# CM_CORE__CKGEN register map
Vendor: Texas Instruments
Peripheral module from a debugger description file (folder TDA2Ex).
Registers are 32-bit, access per field, reset 0x0 unless marked. A register's access mark holds for its fields unless they carry their own. Offsets are as the file gives them; lines under a group give offsets from that group; [hi:lo] are bit positions; {n}, {i} and the like mark numbered series; 'fields as' and 'values as' point back to an identical list; <NAME> marks a mode.

## CM_CORE__CKGEN
0x04 CM_CLKSEL_USB_60MHZ reset 0x1 — Selects the configuration of the divider generating 60MHz clock for USB from the DPLL_USB o/p.
  [0] CLKSEL rw — Select the configuration of the divider
    0=SEL_DIV_1 (Set the divider in bypass mode to support bypass clock from DPLL_USB to pass through without division.); 1=SEL_DIV_8 (Set the divider to divide the DPLL o/p (480MHz typical) by 8 to generate 60MHz clock.)
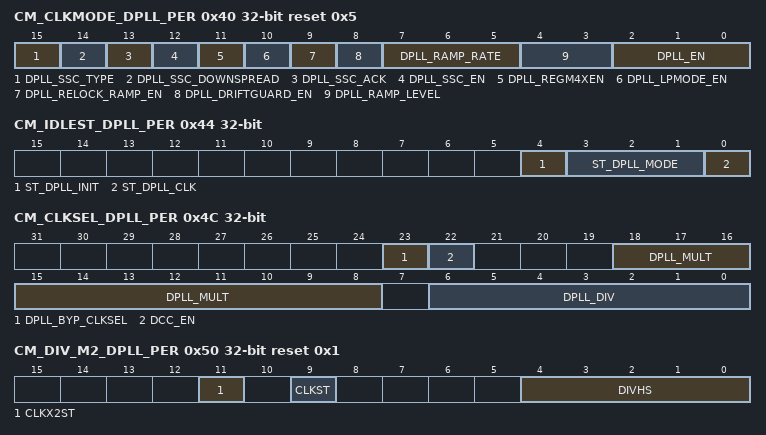
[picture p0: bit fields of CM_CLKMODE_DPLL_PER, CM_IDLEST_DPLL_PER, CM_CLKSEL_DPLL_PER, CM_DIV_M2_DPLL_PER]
0x40 CM_CLKMODE_DPLL_PER reset 0x5 — This register allows controlling the DPLL modes.
  [15] DPLL_SSC_TYPE rw — Select between Triangular and SquareWave Spread Spectrum Clocking
    0=TRIANGULAR (Triangular Spread Spectrum Clocking is selected); 1=SQUARE (Square Wave Spread Spectrum Clocking is selected (only available under proper licensing agreement))
  [14] DPLL_SSC_DOWNSPREAD rw — Control if only low frequency spread is required
    0=FULL_SPREAD (When SSC is enabled, clock frequency is spread on both sides of the programmed frequency); 1=LOW_SPREAD (When SSC is enabled, clock frequency is spread only on the lower side of the programmed frequency)
  [13] DPLL_SSC_ACK ro — Acknowledgement from the DPLL regarding start and stop of Spread Spectrum Clocking feature
    0=DISABLED (SSC has been turned off on PLL o/ps); 1=ENABLED (SSC has been turned on on PLL o/ps)
  [12] DPLL_SSC_EN rw — Enable or disable Spread Spectrum Clocking
    0=DISABLED (SSC disabled); 1=ENABLED (SSC enabled)
  [11] DPLL_REGM4XEN ro — Enable the REGM4XEN mode of the DPLL. Please check the DPLL documentation to check when this mode can be enabled.
    0=DISABLED (REGM4XEN mode of the DPLL is disabled)
  [10] DPLL_LPMODE_EN rw — Set the DPLL in Low Power mode. Check the DPLL documentation to see when this can be enabled.
    0=DISABLED (Low power mode of the DPLL is disabled); 1=ENABLED (Low power mode of the DPLL is enabled)
  [9] DPLL_RELOCK_RAMP_EN rw — If enabled, the clock ramping feature is used applied during the lock process, as well as the relock process. If disabled, the clock ramping feature is used only during the first lock.
  [8] DPLL_DRIFTGUARD_EN rw — This bit allows to enable or disable the automatic recalibration feature of the DPLL. The DPLL will automatically start a recalibration process upon assertion of the DPLL's RECAL flag if this bit is set.
    0=DIASBLED (DRIFTGUARD feature is disabled); 1=ENABLED (DRIFTGUARD feature is enabled)
  [7:5] DPLL_RAMP_RATE rw — Selects the time in terms of DPLL REFCLKs spent at each stage of the clock ramping process
    0=REFCLKX2 (2 REFCLKs); 1=REFCLKX4 (4 REFCLKs); 2=REFCLKX8 (8 REFCLKs); 3=REFCLKX16 (16 REFCLKs); 4=REFCLKX32 (32 REFCLKs); 5=REFCLKX64 (64 REFCLKs); 6=REFCLKX128 (128 REFCLKs); 7=REFCLKX512 (512 REFCLKs)
  [4:3] DPLL_RAMP_LEVEL rw — The DPLL provides an output clock frequency ramping feature when switching from bypass clock to normal clock during lock and re-lock. The frequency ramping will happen in a maximum of 4 steps in frequency before the DPLL's frequency lock indicator is asserted. This register is used to enable/disable the DPLL ramping feature. If enabled, it is also used to select the algorithm used for clock ramping
    0=RAMP_DISABLE (CLKOUT = No ramping CLKOUTX2 = No ramping); 1=RAMP_ALGO1 (CLKOUT = Bypass clk - Fout/8 - Fout/4 - Fout/2 - Fout CLKOUTX2 = Bypass clk - Foutx2/8 - Foutx2/4 - Foutx2/2 - Foutx2); 2=RAMP_ALGO2 (CLKOUT = Bypass clk - Fout/4 - Fout/2 - Fout/1.5 - Fout CLKOUTX2 = Bypass clk - Foutx2/4 - Foutx2/2 - Foutx2/1.5 - Foutx2)
  [2:0] DPLL_EN rw — DPLL control.
    5=DPLL_LP_BYP_MODE (Put the DPLL in Idle Bypass Low Power mode.); 6=DPLL_FR_BYP_MODE (Put the DPLL in Idle Bypass Fast Relock mode.); 7=DPLL_LOCK_MODE (Enables the DPLL in Lock mode)
0x44 CM_IDLEST_DPLL_PER ro — This register allows monitoring DPLL activity. This register is read only and automatically updated. [warm reset insensitive]
  [4] ST_DPLL_INIT — DPLL init status (for debug purpose).
    0=DPLL_NOTINIT (DPLL is not init); 1=DPLL_INIT (DPLL has been init)
  [3:1] ST_DPLL_MODE — DPLL mode status (for debug purpose).
    0=TRANSIENT (Transient state. From reset to any LP idle state or from any power state to any power state (Power states are Low Power Stop mode, Fast Relock Stop mode, Idle Bypass Low Power mode and Idle Bypass Fast Relock mode).); 1=LP_STOP (The DPLL is in Low Power Stop mode.); 2=FR_STOP (The DPLL is in Fast Relock Stop mode.); 5=LP_BYP (The DPLL is in Idle Bypass Low Power mode.); 6=FR_BYP (The DPLL is in Idle Bypass Fast Relock mode.)
  [0] ST_DPLL_CLK — DPLL lock status
    0=DPLL_UNLOCKED (DPLL is either in bypass mode or in stop mode.); 1=DPLL_LOCKED (DPLL is LOCKED)
0x48 CM_AUTOIDLE_DPLL_PER — This register provides automatic control over the DPLL activity.
  [2:0] AUTO_DPLL_MODE rw — DPLL automatic control;
    0=AUTO_CTL_DISABLE (DPLL auto control disabled); 1=AUTO_LP_STOP (The DPLL is automatically put in Low Power Stop mode when its DPLL generated clocks are not required anymore. It is also restarted automatically.); 2=AUTO_FR_STOP (The DPLL is automatically put in Fast Relock Stop mode when its DPLL generated clocks are not required anymore. It is also restarted automatically.); 5=AUTO_LP_BYP (The DPLL is automatically put in Idle Bypass Low Power mode when its DPLL generated clocks are not required anymore. It is also restarted automatically.); 6=AUTO_FR_BYP (The DPLL is automatically put in Idle Bypass Fast Relock mode when its DPLL generated clocks are not required anymore. It is also restarted automatically.)
0x4C CM_CLKSEL_DPLL_PER — This register provides controls over the DPLL.
  [23] DPLL_BYP_CLKSEL rw — Allows control of the BYPASS clock of the PLL and the associated HSDIVIDER. Same as ULOWCLKEN on DPLL. In DPLL Locked mode, 0 - No impact 1 - No impact In DPLL Bypass mode, 0 - CLKINP is selected as the BYPASS clock for CLKOUT/CLKOUTX2 1 - CLKINPULOW is selected as the BYPASS clock for CLKOUT/CLKOUTX2
  [22] DCC_EN ro — Duty-cycle corrector for high frequency clock
    0=DISABLED (Duty-cycle corrector is disabled)
  [18:8] DPLL_MULT rw — DPLL multiplier factor (2 to 2047). (equal to input M of DPLL; M=2 to 2047 = DPLL multiplies by M). [warm reset insensitive]
  [6:0] DPLL_DIV rw — DPLL divider factor (0 to 127) (equal to input N of DPLL; actual division factor is N+1). [warm reset insensitive]
0x50 CM_DIV_M2_DPLL_PER reset 0x1 — This register provides controls over the M2 divider of the DPLL.
  [11] CLKX2ST ro — DPLL CLKOUTX2 status
    0=CLK_GATED (The clock output is gated); 1=CLK_ENABLED (The clock output is enabled)
  [9] CLKST ro — DPLL CLKOUT status
    values as CLKX2ST
  [4:0] DIVHS rw — This field programs the M2 post-divider factor (1 to 31) of DPLL_PER.... .
    1=M2_=_/1; 2=M2_=_/2; 31=RESERVED (M2 = /31)
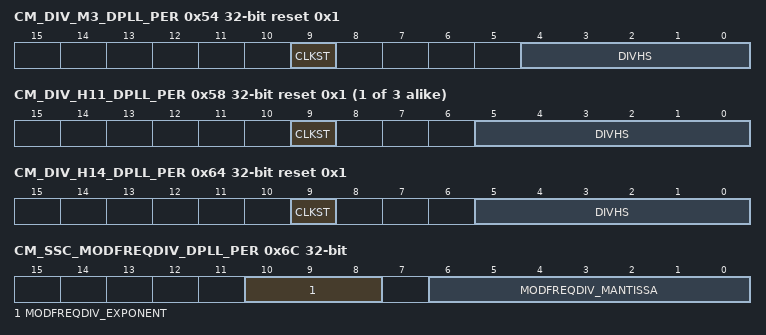
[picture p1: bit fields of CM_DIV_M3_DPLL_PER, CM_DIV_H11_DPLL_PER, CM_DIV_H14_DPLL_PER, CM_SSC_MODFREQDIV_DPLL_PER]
0x54 CM_DIV_M3_DPLL_PER reset 0x1 — This register provides controls over the M3 divider of the DPLL.
  [9] CLKST ro — DPLL CLKOUTHIF status
    values as CM_DIV_M2_DPLL_PER.CLKX2ST
  [4:0] DIVHS rw — This field programs the M3 post-divider factor (1 to 31) of DPLL_PER.... .
    1=M3_=_/1; 2=M3_=_/2; 31=RESERVED (M3 = /31)
{0x2C+4i} CM_DIV_H{i}_DPLL_PER reset 0x1 (i=11..13) — This register provides controls over the CLKOUT{i-10} o/p of the HSDIVIDER1.
  [9] CLKST ro — HSDIVIDER1 CLKOUT{i-10} status
    values as CM_DIV_M2_DPLL_PER.CLKX2ST
  [5:0] DIVHS rw — This field programs the H{i} post-divider factor (1 to 63) of DPLL_PER.... .
    1=H{i}_=_/1; 2=H{i}_=_/2; 63=RESERVED (H{i} = /63)
0x64 CM_DIV_H14_DPLL_PER reset 0x1 — This register provides controls over the CLKOUT4 o/p of the HSDIVIDER1.
  [9] CLKST ro — HSDIVIDER1 CLKOUT4 status
    values as CM_DIV_M2_DPLL_PER.CLKX2ST
  [5:0] DIVHS rw — This field programs the H14 post-divider factor (1 to 63) of DPLL_PER. When a value of 63 is programmed in this register, HS divider will perform division by 2.5 that is divided by 2 at top level.
    2=2; 4=4
0x68 CM_SSC_DELTAMSTEP_DPLL_PER — Control the DeltaMStep parameter for Spread Spectrum Clocking. [warm reset insensitive]
  [19:0] DELTAMSTEP rw — DeltaMStep is split into fractional and integer part. For Triangular Spread Spectrum: [19:18] for integer part, [17:0] for fractional part For Square Wave Spread Spectrum [19:14] for integer part, [13:0] for fractional part
0x6C CM_SSC_MODFREQDIV_DPLL_PER — Control the Modulation Frequency (Fm) for Spread Spectrum Clocking. [warm reset insensitive]
  [10:8] MODFREQDIV_EXPONENT rw — Set the Exponent component of MODFREQDIV factor
  [6:0] MODFREQDIV_MANTISSA rw — Set the Mantissa component of MODFREQDIV factor
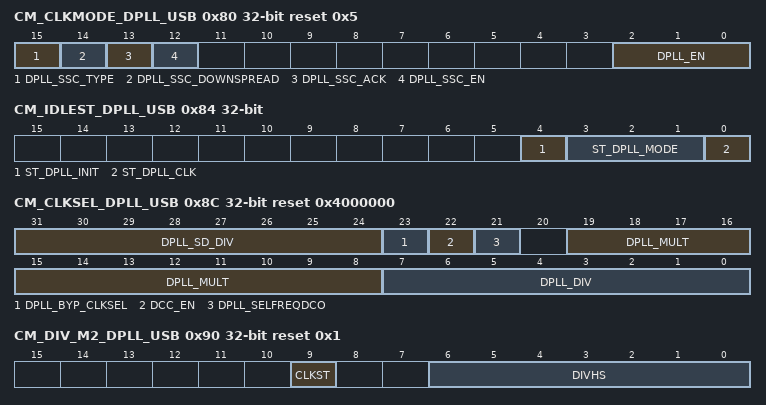
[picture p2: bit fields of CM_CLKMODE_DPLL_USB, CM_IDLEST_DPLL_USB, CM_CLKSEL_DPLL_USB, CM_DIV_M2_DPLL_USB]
0x80 CM_CLKMODE_DPLL_USB reset 0x5 — This register allows controlling the DPLL modes.
  [15] DPLL_SSC_TYPE rw — Select between Triangular and SquareWave Spread Spectrum Clocking
    0=TRIANGULAR (Triangular Spread Spectrum Clocking is selected); 1=SQUARE (SquareWave Spread Spectrum Clocking is selected (only available under proper licensing agreement))
  [14] DPLL_SSC_DOWNSPREAD rw — Control if only low frequency spread is required
    values as CM_CLKMODE_DPLL_PER.DPLL_SSC_DOWNSPREAD
  [13] DPLL_SSC_ACK ro — Acknowledgement from the DPLL regarding start and stop of Spread Spectrum Clocking feature
    values as CM_CLKMODE_DPLL_PER.DPLL_SSC_ACK
  [12] DPLL_SSC_EN rw — Enable or disable Spread Spectrum Clocking
    0=DISABLED (SSC disabled); 1=ENABLED (SSC enabled)
  [2:0] DPLL_EN rw — DPLL control.
    1=DPLL_LP_STP_MODE (Put the DPLL in Low Power Stop mode); 5=DPLL_LP_BYP_MODE (Put the DPLL in Idle Bypass Low Power mode.); 7=DPLL_LOCK_MODE (Enables the DPLL in Lock mode)
0x84 CM_IDLEST_DPLL_USB ro — This register allows monitoring DPLL activity. This register is read only and automatically updated. [warm reset insensitive]
  [4] ST_DPLL_INIT — DPLL init status (for debug purpose).
    values as CM_IDLEST_DPLL_PER.ST_DPLL_INIT
  [3:1] ST_DPLL_MODE — DPLL mode status (for debug purpose).
    0=TRANSIENT (Transient state. From reset to any LP idle state or from any power state to any power state (Power states are Low Power Stop mode, Fast Relock Stop mode, Idle Bypass Low Power mode and Idle Bypass Fast Relock mode).); 1=LP_STOP (The DPLL is in Low Power Stop mode.); 5=LP_BYP (The DPLL is in Idle Bypass Low Power mode.)
  [0] ST_DPLL_CLK — DPLL lock status
    values as CM_IDLEST_DPLL_PER.ST_DPLL_CLK
0x88 CM_AUTOIDLE_DPLL_USB — This register provides automatic control over the DPLL activity.
  [2:0] AUTO_DPLL_MODE rw — DPLL automatic control;
    0=AUTO_CTL_DISABLE (DPLL auto control disabled); 1=AUTO_LP_STOP (The DPLL is automatically put in Low Power Stop mode when its DPLL generated clocks are not required anymore. It is also restarted automatically.); 5=AUTO_LP_BYP (The DPLL is automatically put in Idle Bypass Low Power mode when its DPLL generated clocks are not required anymore. It is also restarted automatically.)
0x8C CM_CLKSEL_DPLL_USB reset 0x4000000 — This register provides controls over the DPLL.
  [31:24] DPLL_SD_DIV rw — Sigma-Delta divider select (2-255). This factor must be set by s/w to ensure optimum jitter performance. DPLL_SD_DIV = CEILING ([DPLL_MULT/(DPLL_DIV+1)] * CLKINP / 250), where CLKINP is the input clock of the DPLL in MHz). Must be set with M and N factors, and must not be changed once DPLL is locked.
  [23] DPLL_BYP_CLKSEL rw — Allows control of the BYPASS clock of the PLL and the associated HSDIVIDER. Same as ULOWCLKEN on DPLL. In DPLL Locked mode, 0 - No impact 1 - No impact In DPLL Bypass mode, 0 - CLKINP is selected as the BYPASS clock for CLKOUT 1 - CLKINPULOW is selected as the BYPASS clock for CLKOUT
  [22] DCC_EN ro — Duty-cycle corrector for high frequency clock
    0=DISABLED (Duty-cycle corrector is disabled)
  [21] DPLL_SELFREQDCO rw — select DCO output according to required frequency.
    0=LS_CLK (DCO clock is 1500MHz SELFREQDCO input of DPLL is set to '010'); 1=HS_CLK (DCO clock is 1250MHz SELFREQDCO input of DPLL is set to '100')
  [19:8] DPLL_MULT rw — DPLL multiplier factor (2 to 4095). (equal to input M of DPLL; M=2 to 4095 = DPLL multiplies by M). [warm reset insensitive]
  [7:0] DPLL_DIV rw — DPLL divider factor (0 to 255) (equal to input N of DPLL; actual division factor is N+1). [warm reset insensitive]
0x90 CM_DIV_M2_DPLL_USB reset 0x1 — This register provides controls over the M2 divider of the DPLL.
  [9] CLKST ro — DPLL CLKOUT status
    values as CM_DIV_M2_DPLL_PER.CLKX2ST
  [6:0] DIVHS rw — This field programs the M2 post-divider factor (1 to 127) of DPLL_USB.... .
    1=M2_=_/1; 2=M2_=_/2; 127=RESERVED (M2 = /127)
0xA8 CM_SSC_DELTAMSTEP_DPLL_USB — Control the DeltaMStep parameter for Spread Spectrum Clocking. [warm reset insensitive]
  [20:0] DELTAMSTEP rw — DeltaMStep is split into fractional and integer part. For Triangular Spread Spectrum: [20:18] for integer part, [17:0] for fractional part For Square Wave Spread Spectrum [19:14] for integer part, [13:0] for fractional part
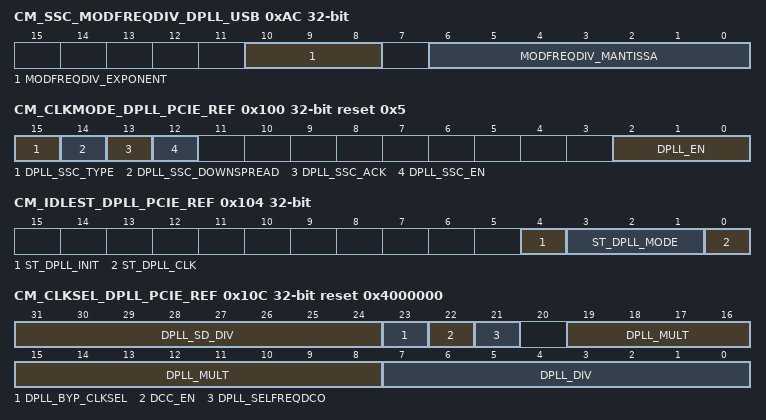
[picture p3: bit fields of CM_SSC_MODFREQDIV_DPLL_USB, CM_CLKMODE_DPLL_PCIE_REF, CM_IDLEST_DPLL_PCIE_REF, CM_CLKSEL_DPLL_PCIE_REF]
0xAC CM_SSC_MODFREQDIV_DPLL_USB — Control the Modulation Frequency (Fm) for Spread Spectrum Clocking. [warm reset insensitive]
  fields as CM_SSC_MODFREQDIV_DPLL_PER
0xB4 CM_CLKDCOLDO_DPLL_USB ro — This register provides status over CLKDCOLDO output of the DPLL.
  [9] ST_DPLL_CLKDCOLDO — DPLL CLKDCOLDO status
    values as CM_DIV_M2_DPLL_PER.CLKX2ST
0x100 CM_CLKMODE_DPLL_PCIE_REF reset 0x5 — This register allows controlling the DPLL modes.
  fields as CM_CLKMODE_DPLL_USB
0x104 CM_IDLEST_DPLL_PCIE_REF ro — This register allows monitoring DPLL activity. This register is read only and automatically updated. [warm reset insensitive]
  fields as CM_IDLEST_DPLL_USB
0x108 CM_AUTOIDLE_DPLL_PCIE_REF — This register provides automatic control over the DPLL activity.
  fields as CM_AUTOIDLE_DPLL_USB
0x10C CM_CLKSEL_DPLL_PCIE_REF reset 0x4000000 — This register provides controls over the DPLL.
  [31:24] DPLL_SD_DIV rw — Sigma-Delta divider select (2-255). This factor must be set by s/w to ensure optimum jitter performance. DPLL_SD_DIV = CEILING ([DPLL_MULT/(DPLL_DIV+1)] * CLKINP / 250), where CLKINP is the input clock of the DPLL in MHz). Must be set with M and N factors, and must not be changed once DPLL is locked.
  [23] DPLL_BYP_CLKSEL ro — Allows control of the BYPASS clock of the PLL and the associated HSDIVIDER. Same as ULOWCLKEN on DPLL. In DPLL Locked mode, 0 - No impact 1 - No impact In DPLL Bypass mode, 0 - CLKINP is selected as the BYPASS clock for CLKOUT 1 - CLKINPULOW is selected as the BYPASS clock for CLKOUT
  [22] DCC_EN ro — Duty-cycle corrector for high frequency clock
    0=DISABLED (Duty-cycle corrector is disabled)
  [21] DPLL_SELFREQDCO rw — select DCO output according to required frequency.
    values as CM_CLKSEL_DPLL_USB.DPLL_SELFREQDCO
  [19:8] DPLL_MULT rw — DPLL multiplier factor (2 to 4095). (equal to input M of DPLL; M=2 to 4095 = DPLL multiplies by M). [warm reset insensitive]
  [7:0] DPLL_DIV rw — DPLL divider factor (0 to 255) (equal to input N of DPLL; actual division factor is N+1). [warm reset insensitive]
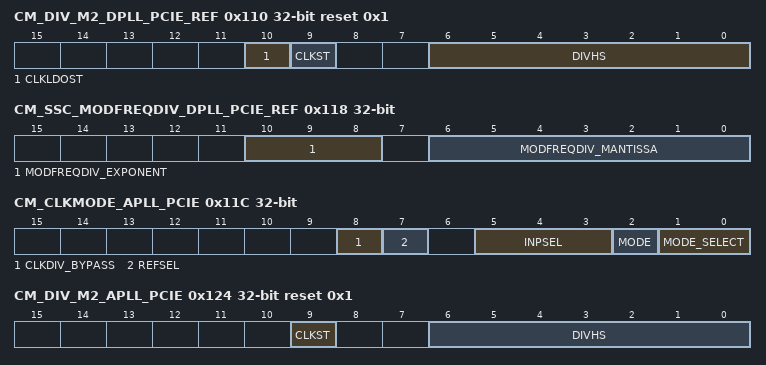
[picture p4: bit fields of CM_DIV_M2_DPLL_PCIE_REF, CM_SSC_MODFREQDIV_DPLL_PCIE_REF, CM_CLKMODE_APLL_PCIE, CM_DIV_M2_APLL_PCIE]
0x110 CM_DIV_M2_DPLL_PCIE_REF reset 0x1 — This register provides controls over the M2 divider of the DPLL.
  [10] CLKLDOST ro — DPLL CLKOUTLDO status
    0=CLK_GATED (Output clock is gated); 1=CLK_ENABLED (Output clock is enabled)
  [9] CLKST ro — DPLL CLKOUT status
    values as CM_DIV_M2_DPLL_PER.CLKX2ST
  [6:0] DIVHS rw — This field programs the M2 post-divider factor (1 to 127) of DPLL_PCIE_REF.... .
    1=M2_=_/1; 2=M2_=_/2; 127=RESERVED (M2 = /127)
0x114 CM_SSC_DELTAMSTEP_DPLL_PCIE_REF — Control the DeltaMStep parameter for Spread Spectrum Clocking. [warm reset insensitive]
  fields as CM_SSC_DELTAMSTEP_DPLL_USB
0x118 CM_SSC_MODFREQDIV_DPLL_PCIE_REF — Control the Modulation Frequency (Fm) for Spread Spectrum Clocking. [warm reset insensitive]
  fields as CM_SSC_MODFREQDIV_DPLL_PER
0x11C CM_CLKMODE_APLL_PCIE — This register allows controlling the APLL modes.
  [8] CLKDIV_BYPASS rw
    0=PCIEDIVBY2_BYPASS_0 (Division of CLKVCOLDO_DIV clock is controlled by OUTSEL pin driven by PCIE controlleur. If OUTSEL is '0', CLKVCOLDO_DIV is at same frequency than CLKVCOLDO output If OUTSEL is '1', CLKVCOLDO_DIV is at CLKVCOLDO divide by 2 frequency); 1=PCIEDIVBY2_BYPASS_1 (CLKVCOLDO_DIV clock is not divided by 2 (CLKVCOLDO_DIV is at same frequency than CLKVCOLDO output))
  [7] REFSEL rw — Select source of reference input clock
    0=CLKREF_ADPLL (APLL reference input clock is from ADPLL); 1=CLKREF_ACSPCIE (APLL reference input clock is from ACSPCIE)
  [5:3] INPSEL ro — Reference clock is 100MHz.
  [2] MODE ro — APLLPCIE Mode Status
    0=PCIE (APLLPCIE Mode Status)
  [1:0] MODE_SELECT rw — Control APLL mode.Note:Please note that setting [1:0] MODE_SELECT bitfield to 0x0 does not disable the APLL_PCIE. In order to disable the APLL_PCIE, the user needs to disable PCIe_SSx (where x = 1 or 2) using the CM_PCIE_ PCIESSx_CLKCTRL[1:0] MODULEMODE registers. When PCIe_SS is disabled, the PRCM module automatically disables the APLL_PCIE. .
    1=APLL_FORCE_LOCK_MODE (Put the APLL in Force Lock mode); 2=APLL_FORCE_IDLE_MODE (Put the APLL in Auto Idle mode)
0x120 CM_IDLEST_APLL_PCIE ro — This register allows monitoring APLL activity. This register is read only and automatically updated. [warm reset insensitive]
  [0] ST_APLL_CLK — APLL lock status
    0=APLL_UNLOCKED (APLL is either in bypass mode or in stop mode.); 1=APLL_LOCKED (APLL is LOCKED)
0x124 CM_DIV_M2_APLL_PCIE ro reset 0x1 — This register provides controls over the M2 divider of the DPLL.
  [9] CLKST — DPLL CLKOUT status
    values as CM_DIV_M2_DPLL_PER.CLKX2ST
  [6:0] DIVHS — DPLL M2 post-divider factor (1 to 127). (RESERVED)
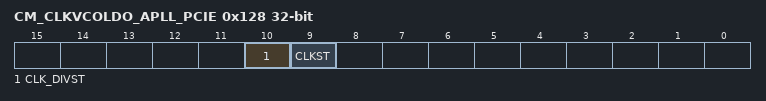
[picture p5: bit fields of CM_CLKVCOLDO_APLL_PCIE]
0x128 CM_CLKVCOLDO_APLL_PCIE ro — This register provides status over CLKVCOLDO and CLKVCOLDO_DIV outputs of the APLL.
  [10] CLK_DIVST — APLL CLKVCOLDO_DIV status
    values as CM_DIV_M2_DPLL_PER.CLKX2ST
  [9] CLKST — APLL CLKVCOLDO status
    values as CM_DIV_M2_DPLL_PER.CLKX2ST
